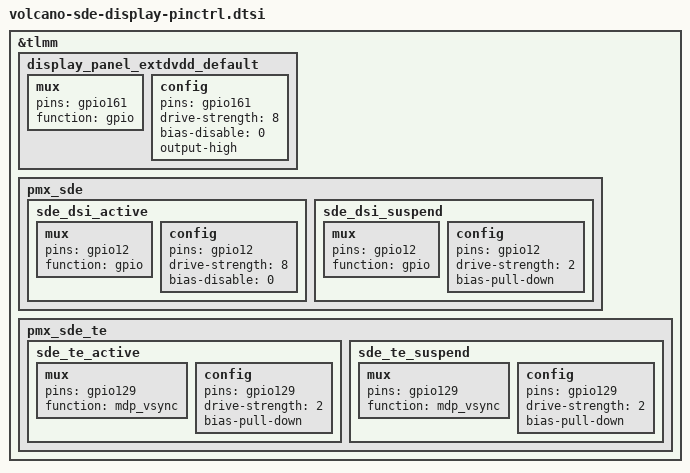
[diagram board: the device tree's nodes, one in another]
&tlmm {
	display_panel_extdvdd_default: display_panel_extdvdd_default {
		mux {
			pins = "gpio161";
			function = "gpio";
		};

		config {
			pins = "gpio161";
			drive-strength = <8>;
			bias-disable = <0>;
			output-high;
		};
	};

	pmx_sde: pmx_sde {
		sde_dsi_active: sde_dsi_active {
			mux {
				pins = "gpio12";
				function = "gpio";
			};

			config {
				pins = "gpio12";
				drive-strength = <8>;   /* 8 mA */
				bias-disable = <0>;   /* no pull */
			};
		};

		sde_dsi_suspend: sde_dsi_suspend {
			mux {
				pins = "gpio12";
				function = "gpio";
			};

			config {
				pins = "gpio12";
				drive-strength = <2>;   /* 2 mA */
				bias-pull-down;         /* PULL DOWN */
			};
		};
	};

	pmx_sde_te: pmx_sde_te {
		sde_te_active: sde_te_active {
			mux {
				pins = "gpio129";
				function = "mdp_vsync";
			};

			config {
				pins = "gpio129";
				drive-strength = <2>;   /* 2 mA */
				bias-pull-down;         /* PULL DOWN */
			};
		};

		sde_te_suspend: sde_te_suspend {
			mux {
				pins = "gpio129";
				function = "mdp_vsync";
			};

			config {
				pins = "gpio129";
				drive-strength = <2>;   /* 2 mA */
				bias-pull-down;         /* PULL DOWN */
			};
		};
	};
};
